VERSION ""

NS_ :

BS_:

BU_:

BO_ 0 MOTOR_BOARD_BOOTLOADER_CTRL: 5 Vector__XXX
	SG_ Command : 0|8@1+ (1,0) [0|5] "" Vector__XXX
    SG_ CRC : 8|32@1+ (1,0) [0|0] "" Vector_XXX

BO_ 1 MOTOR_BOARD_BOOTLOADER_FIRMWARE: 8 Vector__XXX
	SG_ Firmware : 0|64@1+ (1,0) [0|0] "" Vector__XXX

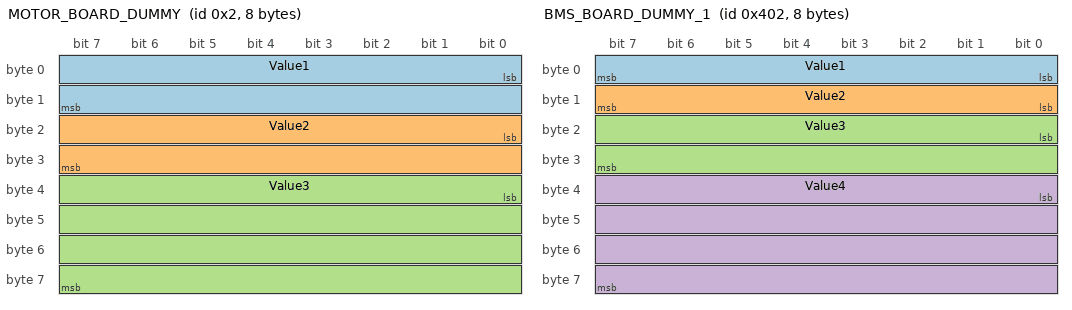
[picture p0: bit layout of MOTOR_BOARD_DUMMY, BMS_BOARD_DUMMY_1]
BO_ 2 MOTOR_BOARD_DUMMY: 8 Vector__XXX
	SG_ Value1 : 0|16@1+ (1,20) [0|250] "km/h" Vector__XXX
	SG_ Value2 : 16|16@1+ (1,0) [0|60] "C" Vector__XXX
	SG_ Value3 : 32|32@1- (0.1,0) [-200|1200] "" Vector__XXX

BO_ 1024 BMS_BOARD_BOOTLOADER_CTRL: 5 Vector__XXX
	SG_ Command : 0|8@1+ (1,0) [0|5] "" Vector__XXX
	SG_ CRC : 8|32@1+ (1,0) [0|0] "" Vector_XXX

BO_ 1025 BMS_BOARD_BOOTLOADER_FIRMWARE: 8 Vector__XXX
	SG_ Firmware : 0|64@1+ (1,0) [0|0] "" Vector__XXX

BO_ 1026 BMS_BOARD_DUMMY_1: 8 Vector__XXX
	SG_ Value1 : 0|8@1+ (1,0) [0|10] "" Vector__XXX
	SG_ Value2 : 8|8@1+ (1,0) [0|100] "" Vector__XXX
	SG_ Value3 : 16|16@1+ (1,0) [0|1000] "" Vector__XXX
	SG_ Value4 : 32|32@1+ (1,0) [0|10000] "" Vector__XXX

BO_ 1027 BMS_BOARD_DUMMY_2: 8 Vector__XXX
	SG_ Value1 : 0|32@1+ (1,0) [0|10000] "" Vector__XXX
	SG_ Value2 : 32|32@1- (1,0) [-10000|10000] "" Vector__XXX

CM_ BO_ 0 "Bootloader Control Message";
CM_ BO_ 1 "Bootloader Firmware Fragment";
CM_ SG_ 1 Firmware "Firmware Fragment";
CM_ BO_ 2 "Some info for motor board";
CM_ BO_ 1024 "Bootloader Control Message";
CM_ BO_ 1025 "Bootloader Firmware Fragment";
CM_ SG_ 1025 Firmware "Firmware Fragment";
CM_ BO_ 1026 "Some info for bms board";
CM_ BO_ 1027 "Some info for bms board";
BA_DEF_ BO_  "VFrameFormat" ENUM  "StandardCAN","ExtendedCAN","reserved","J1939PG";
BA_DEF_  "DatabaseVersion" STRING ;
BA_DEF_  "BusType" STRING ;
BA_DEF_  "ProtocolType" STRING ;
BA_DEF_  "DatabaseCompiler" STRING ;
BA_DEF_DEF_  "VFrameFormat" "J1939PG";
BA_DEF_DEF_  "DatabaseVersion" "DEMO PLUS";
BA_DEF_DEF_  "BusType" "";
BA_DEF_DEF_  "ProtocolType" "";
BA_DEF_DEF_  "DatabaseCompiler" "";
BA_ "BusType" "CAN";
BA_ "DatabaseCompiler" "CSS ELECTRONICS (WWW.CSSELECTRONICS.COM)";
BA_ "DatabaseVersion" "1.0.0";
